# ADuCM4050 register map
Vendor: Analog Devices; Series: ADuCM4050; File version: 1p0
CPU: CM4 r0p1, little endian, MPU, FPU, 3 interrupt priority bits
Registers are 32-bit, read-write, reset 0x0 unless marked. A register's access mark holds for its fields unless they carry their own. Offsets are from the block's base; [hi:lo] are bit positions; 'fields as' and 'values as' point back to an identical list.

## SPORT0 — Serial Port
Base 0x40038000
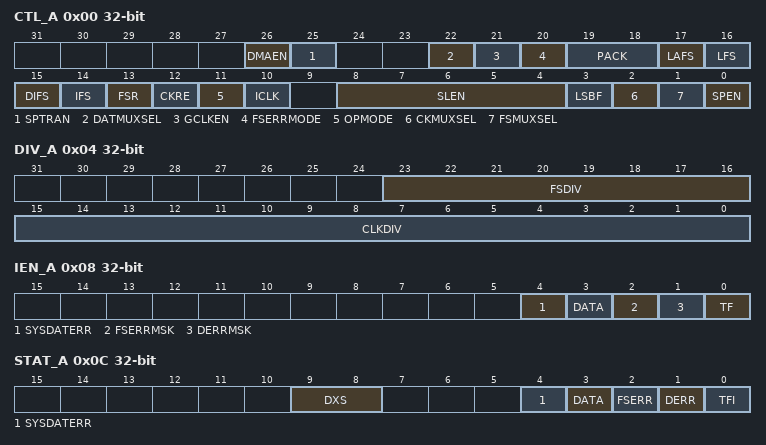
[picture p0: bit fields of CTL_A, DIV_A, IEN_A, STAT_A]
0x00 CTL_A — Half SPORT 'A' Control Register
  [26] DMAEN — DMA Enable
  [25] SPTRAN — Serial Port Transfer Direction
    0=CTL_RX (Receive); 1=CTL_TX (Transmit)
  [22] DATMUXSEL — Data Multiplexer select
  [21] GCLKEN — Gated Clock Enable
    0=CTL_GCLK_DIS (Disable); 1=CTL_GCLK_EN (Enable)
  [20] FSERRMODE — Frame Sync Error Operation
  [19:18] PACK — Packing Enable
    0=CTL_PACK_DIS (Disable); 1=CTL_PACK_8BIT (8-bit packing enable); 2=CTL_PACK_16BIT (16-bit packing enable)
  [17] LAFS — Late Frame Sync
    0=CTL_EARLY_FS (Early frame sync); 1=CTL_LATE_FS (Late frame sync)
  [16] LFS — Active-Low Frame Sync
    0=CTL_FS_LO (Active high frame sync); 1=CTL_FS_HI (Active low frame sync)
  [15] DIFS — Data-Independent Frame Sync
    0=CTL_DATA_DEP_FS (Data-dependent frame sync); 1=CTL_DATA_INDP_FS (Data-independent frame sync)
  [14] IFS — Internal Frame Sync
    0=CTL_EXTERNAL_FS (External frame sync); 1=CTL_INTERNAL_FS (Internal frame sync)
  [13] FSR — Frame Sync Required
    0=CTL_FS_NOT_REQ (No frame sync required); 1=CTL_FS_REQ (Frame sync required)
  [12] CKRE — Clock Rising Edge
    0=CTL_CLK_FALL_EDGE (Clock falling edge); 1=CTL_CLK_RISE_EDGE (Clock rising edge)
  [11] OPMODE — Operation mode
    0=CTL_SERIAL (DSP standard); 1=CTL_TIMER_EN_MODE (Timer_enable mode)
  [10] ICLK — Internal Clock
    0=CTL_EXTERNAL_CLK (External clock); 1=CTL_INTERNAL_CLK (Internal clock)
  [8:4] SLEN range 0x00000000..0x0000001F — Serial Word Length
  [3] LSBF — Least-Significant Bit First
    0=CTL_MSB_FIRST (MSB first sent/received); 1=CTL_LSB_FIRST (LSB first sent/received)
  [2] CKMUXSEL — Clock Multiplexer Select
    0=CTL_CLK_MUX_DIS (Disable serial clock multiplexing); 1=CTL_CLK_MUX_EN (Enable serial clock multiplexing)
  [1] FSMUXSEL — Frame Sync Multiplexer Select
    0=CTL_FS_MUX_DIS (Disable frame sync multiplexing); 1=CTL_FS_MUX_EN (Enable frame sync multiplexing)
  [0] SPEN — Serial Port Enable
    0=CTL_DIS (Disable); 1=CTL_EN (Enable)
0x04 DIV_A — Half SPORT 'A' Divisor Register
  [23:16] FSDIV range 0x00000000..0x000000FF — Frame Sync Divisor
  [15:0] CLKDIV range 0x00000000..0x0000FFFF — Clock Divisor
0x08 IEN_A — Half SPORT A's Interrupt Enable register
  [4] SYSDATERR — Data error for system writes or reads
  [3] DATA — Data request interrupt to the core
  [2] FSERRMSK — Frame Sync Error (Interrupt) Mask
  [1] DERRMSK — Data Error (Interrupt) Mask
  [0] TF — Transfer Finish Interrupt Enable
    0=CTL_TXFIN_DIS (Transfer finish Interrupt is disabled); 1=CTL_TXFIN_EN (Transfer Finish Interrupt is Enabled)
0x0C STAT_A — Half SPORT 'A' Status register
  [9:8] DXS ro — Data Transfer Buffer Status
    0=CTL_EMPTY (Empty); 2=CTL_PART_FULL (Partially full); 3=CTL_FULL (Full)
  [4] SYSDATERR ro — System Data Error Status
  [3] DATA ro — Data Buffer status
  [2] FSERR ro — Frame Sync Error Status
  [1] DERR ro — Data Error Status
  [0] TFI ro — Transmit Finish Interrupt Status
0x10 NUMTRAN_A — Half SPORT A Number of transfers register
  [11:0] VALUE range 0x00000000..0x00000FFF — Number of transfers (Half SPORT A)
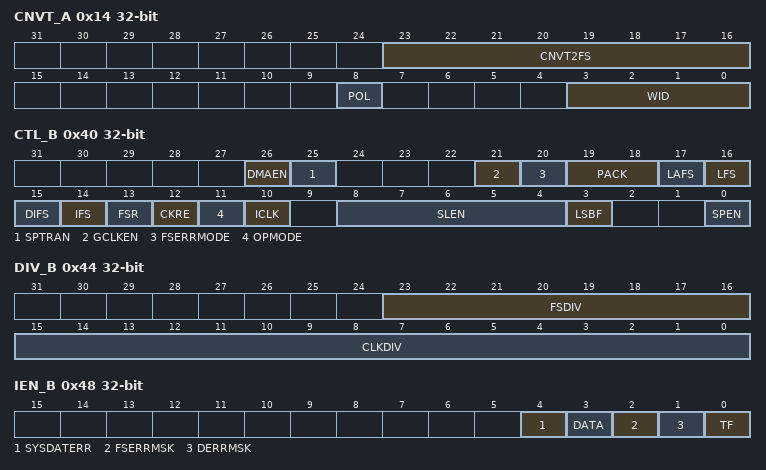
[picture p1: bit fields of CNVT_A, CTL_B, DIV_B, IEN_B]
0x14 CNVT_A — Half SPORT 'A' CNV width
  [23:16] CNVT2FS range 0x00000000..0x000000FF — CNV to FS duration: Half SPORT A
  [8] POL — Polarity of the CNV signal
  [3:0] WID range 0x00000000..0x0000000F — CNV signal width: Half SPORT A
0x20 TX_A — Half SPORT 'A' Tx Buffer Register
  [31:0] VALUE wo range 0x00000000..0xFFFFFFFF — Transmit Buffer
0x28 RX_A — Half SPORT 'A' Rx Buffer Register
  [31:0] VALUE ro — Receive Buffer
0x40 CTL_B — Half SPORT 'B' Control Register
  [26] DMAEN — DMA Enable
  [25] SPTRAN — Serial Port Transfer Direction
  [21] GCLKEN — Gated Clock Enable
  [20] FSERRMODE — Frame Sync Error Operation
  [19:18] PACK — Packing Enable
    values as CTL_A.PACK
  [17] LAFS — Late Frame Sync
  [16] LFS — Active-Low Frame Sync
  [15] DIFS — Data-Independent Frame Sync
  [14] IFS — Internal Frame Sync
  [13] FSR — Frame Sync Required
  [12] CKRE — Clock Rising Edge
  [11] OPMODE — Operation mode
  [10] ICLK — Internal Clock
  [8:4] SLEN range 0x00000000..0x0000001F — Serial Word Length
  [3] LSBF — Least-Significant Bit First
  [0] SPEN — Serial Port Enable
0x44 DIV_B — Half SPORT 'B' Divisor Register
  fields as DIV_A
0x48 IEN_B — Half SPORT B's Interrupt Enable register
  [4] SYSDATERR — Data error for system writes or reads
  [3] DATA — Data request interrupt to the core
  [2] FSERRMSK — Frame Sync Error (Interrupt) Mask
  [1] DERRMSK — Data Error (Interrupt) Mask
  [0] TF — Transmit Finish Interrupt Enable
    0=CTL_TXFIN_DIS (Transfer Finish Interrupt is disabled); 1=CTL_TXFIN_EN (Transfer Finish Interrupt is Enabled)
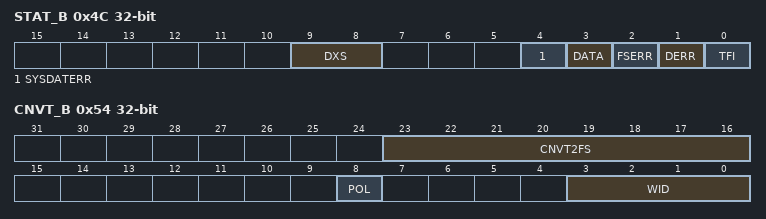
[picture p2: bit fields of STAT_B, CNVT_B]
0x4C STAT_B — Half SPORT 'B' Status register
  fields as STAT_A
0x50 NUMTRAN_B — Half SPORT B Number of transfers register
  [11:0] VALUE range 0x00000000..0x00000FFF — Number of transfers (Half SPORT B)
0x54 CNVT_B — Half SPORT 'B' CNV width register
  [23:16] CNVT2FS range 0x00000000..0x000000FF — CNV to FS duration: Half SPORT B
  [8] POL — Polarity of the CNV signal
  [3:0] WID range 0x00000000..0x0000000F — CNV signal width: Half SPORT B
0x60 TX_B — Half SPORT 'B' Tx Buffer Register
  [31:0] VALUE wo range 0x00000000..0xFFFFFFFF — Transmit Buffer
0x68 RX_B — Half SPORT 'B' Rx Buffer Register
  [31:0] VALUE ro — Receive Buffer
